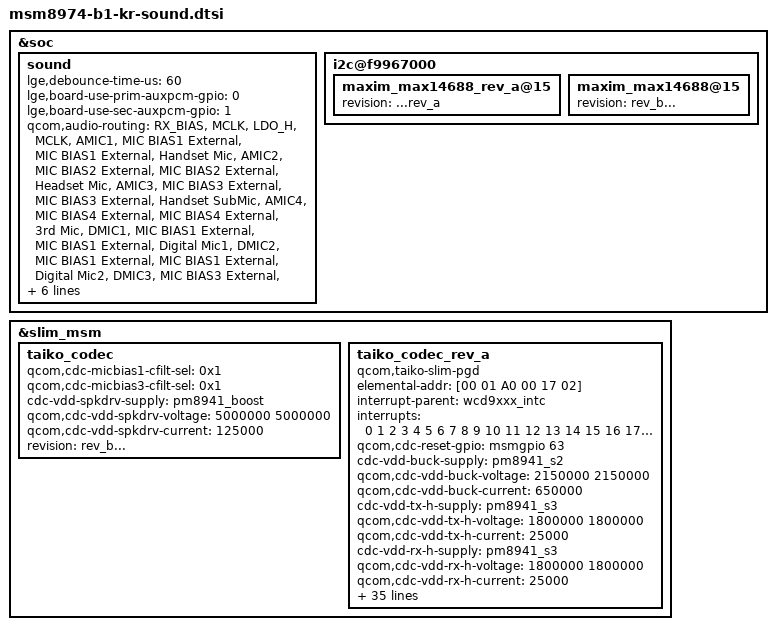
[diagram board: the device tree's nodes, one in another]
/* Copyright (c) 2013, LGE Electronics. All rights reserved.
 *
 * This program is free software; you can redistribute it and/or modify
 * it under the terms of the GNU General Public License version 2 and
 * only version 2 as published by the Free Software Foundation.
 *
 * This program is distributed in the hope that it will be useful,
 * but WITHOUT ANY WARRANTY; without even the implied warranty of
 * MERCHANTABILITY or FITNESS FOR A PARTICULAR PURPOSE.  See the
 * GNU General Public License for more details.
 */

&soc {

	sound {
		lge,debounce-time-us = <60>;
		lge,board-use-prim-auxpcm-gpio = <0>;
		lge,board-use-sec-auxpcm-gpio = <1>;

		qcom,audio-routing =
			"RX_BIAS", "MCLK",
			"LDO_H", "MCLK",
			"AMIC1", "MIC BIAS1 External",
			"MIC BIAS1 External", "Handset Mic",
			"AMIC2", "MIC BIAS2 External",
			"MIC BIAS2 External", "Headset Mic",
			"AMIC3", "MIC BIAS3 External",
			"MIC BIAS3 External", "Handset SubMic",
			"AMIC4", "MIC BIAS4 External",
			"MIC BIAS4 External", "3rd Mic",
			"DMIC1", "MIC BIAS1 External",
			"MIC BIAS1 External", "Digital Mic1",
			"DMIC2", "MIC BIAS1 External",
			"MIC BIAS1 External", "Digital Mic2",
			"DMIC3", "MIC BIAS3 External",
			"MIC BIAS3 External", "Digital Mic3",
			"DMIC4", "MIC BIAS3 External",
			"MIC BIAS3 External", "Digital Mic4",
			"DMIC5", "MIC BIAS4 External",
			"MIC BIAS4 External", "Digital Mic5",
			"DMIC6", "MIC BIAS4 External",
			"MIC BIAS4 External", "Digital Mic6";
	};

       i2c@f9967000 {
	       maxim_max14688_rev_a@15 {
			status = "ok";
                     revision = "...rev_a";
			};
              maxim_max14688@15 {
			status = "ok";
                     revision = "rev_b...";
			};
	};
};

&slim_msm {
	taiko_codec {
              qcom,cdc-micbias1-cfilt-sel = <0x1>;
              qcom,cdc-micbias3-cfilt-sel = <0x1>;
              cdc-vdd-spkdrv-supply = <&pm8941_boost>;
              qcom,cdc-vdd-spkdrv-voltage = <5000000 5000000>;
              qcom,cdc-vdd-spkdrv-current = <125000>;
              revision = "rev_b...";
       };

       taiko_codec_rev_a {
              compatible = "qcom,taiko-slim-pgd";
              elemental-addr = [00 01 A0 00 17 02];

              interrupt-parent = <&wcd9xxx_intc>;
              interrupts = <0 1 2 3 4 5 6 7 8 9 10 11 12 13 14 15 16
                            17 18 19 20 21 22 23 24 25 26 27 28 29
                            30>;

              qcom,cdc-reset-gpio = <&msmgpio 63 0>;

              cdc-vdd-buck-supply = <&pm8941_s2>;
              qcom,cdc-vdd-buck-voltage = <2150000 2150000>;
              qcom,cdc-vdd-buck-current = <650000>;

              cdc-vdd-tx-h-supply = <&pm8941_s3>;
              qcom,cdc-vdd-tx-h-voltage = <1800000 1800000>;
              qcom,cdc-vdd-tx-h-current = <25000>;

              cdc-vdd-rx-h-supply = <&pm8941_s3>;
		qcom,cdc-vdd-rx-h-voltage = <1800000 1800000>;
              qcom,cdc-vdd-rx-h-current = <25000>;

              cdc-vddpx-1-supply = <&pm8941_s3>;
              qcom,cdc-vddpx-1-voltage = <1800000 1800000>;
              qcom,cdc-vddpx-1-current = <10000>;

              cdc-vdd-a-1p2v-supply = <&pm8941_l1>;
              qcom,cdc-vdd-a-1p2v-voltage = <1225000 1225000>;
              qcom,cdc-vdd-a-1p2v-current = <10000>;

              cdc-vddcx-1-supply = <&pm8941_l1>;
              qcom,cdc-vddcx-1-voltage = <1225000 1225000>;
              qcom,cdc-vddcx-1-current = <10000>;

              cdc-vddcx-2-supply = <&pm8941_l1>;
              qcom,cdc-vddcx-2-voltage = <1225000 1225000>;
              qcom,cdc-vddcx-2-current = <10000>;

              qcom,cdc-static-supplies = "cdc-vdd-buck",
                                         "cdc-vdd-tx-h",
                                         "cdc-vdd-rx-h",
                                         "cdc-vddpx-1",
                                         "cdc-vdd-a-1p2v",
                                         "cdc-vddcx-1",
                                         "cdc-vddcx-2";

              qcom,cdc-micbias-ldoh-v = <0x3>;
              qcom,cdc-micbias-cfilt1-mv = <1800>;
              qcom,cdc-micbias-cfilt2-mv = <2700>;
              qcom,cdc-micbias-cfilt3-mv = <1800>;
              qcom,cdc-micbias1-cfilt-sel = <0x1>;
              qcom,cdc-micbias2-cfilt-sel = <0x1>;
              qcom,cdc-micbias3-cfilt-sel = <0x1>;
              qcom,cdc-micbias4-cfilt-sel = <0x1>;
              qcom,cdc-mclk-clk-rate = <9600000>;
              qcom,cdc-slim-ifd = "taiko-slim-ifd";
              qcom,cdc-slim-ifd-elemental-addr = [00 00 A0 00 17 02];
              qcom,cdc-dmic-sample-rate = <4800000>;
              qcom,cdc-micbias3-ext-cap;
              qcom,cdc-micbias4-ext-cap;
              cdc-vdd-spkdrv-supply = <&pm8941_boost>;
              qcom,cdc-vdd-spkdrv-voltage = <5000000 5000000>;
              qcom,cdc-vdd-spkdrv-current = <125000>;
              qcom,cdc-on-demand-supplies = "cdc-vdd-spkdrv";
              revision = "...rev_a";
       };
};
